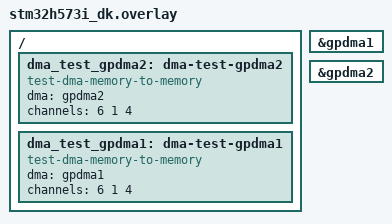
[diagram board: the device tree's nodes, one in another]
/*
 * Copyright (c) 2023 STMicroelectronics
 * Copyright (c) Benjamin Björnsson <benjamin.bjornsson@gmail.com>
 *
 * SPDX-License-Identifier: Apache-2.0
 */

/ {
	dma_test_gpdma2: dma-test-gpdma2 {
		compatible = "test-dma-memory-to-memory";
		dma = <&gpdma2>;
		channels = <6 1 4>;
	};

	dma_test_gpdma1: dma-test-gpdma1 {
		compatible = "test-dma-memory-to-memory";
		dma = <&gpdma1>;
		channels = <6 1 4>;
	};
};

&gpdma1 {
	status = "okay";
};

&gpdma2 {
	status = "okay";
};
